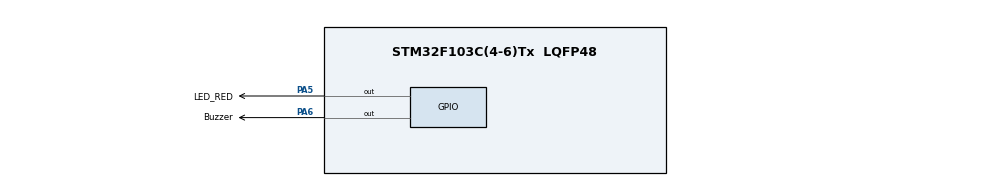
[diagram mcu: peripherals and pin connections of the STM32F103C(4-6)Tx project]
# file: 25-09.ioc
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Mcu.Family=STM32F1
Mcu.Name=STM32F103C(4-6)Tx
Mcu.Package=LQFP48
NVIC.PriorityGroup=NVIC_PRIORITYGROUP_4
NVIC.TIM2_IRQn=true\:0\:0\:false\:false\:true\:true\:true
PA5.GPIO_Label=LED_RED
PA5.Signal=GPIO_Output
PA6.GPIO_Label=Buzzer
PA6.Signal=GPIO_Output
ProjectManager.HeapSize=0x200
ProjectManager.StackSize=0x400
ProjectManager.TargetToolchain=STM32CubeIDE
RCC.APB1Freq_Value=8000000
RCC.APB2Freq_Value=8000000
TIM2.Period=9
TIM2.Prescaler=7999
VP_SYS_VS_ND.Mode=No_Debug
VP_TIM2_VS_ClockSourceINT.Mode=Internal
board=custom

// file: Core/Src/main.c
/* USER CODE BEGIN Header */
/**
  ******************************************************************************
  * @file           : main.c
  * @brief          : Main program body
  ******************************************************************************
  * @attention
  *
  * <h2><center>&copy; Copyright (c) 2022 STMicroelectronics.
  * All rights reserved.</center></h2>
  *
  * This software component is licensed by ST under BSD 3-Clause license,
  * the "License"; You may not use this file except in compliance with the
  * License. You may obtain a copy of the License at:
  *                        opensource.org/licenses/BSD-3-Clause
  *
  ******************************************************************************
  */
/* USER CODE END Header */
#include "main.h"

/* USER CODE BEGIN Includes */
#include "software_timer.h"
/* USER CODE END Includes */

TIM_HandleTypeDef htim2;

void SystemClock_Config(void);
static void MX_GPIO_Init(void);
static void MX_TIM2_Init(void);
void Turn_On_LED (void);
void Turn_Off_LED (void);
void Turn_On_Buzzer (void);
void Turn_Off_Buzzer (void);
void SystemStatusUpdate (void);
const uint8_t delayTime = 10;
static uint32_t ledOnTime, ledOffTime, u32CounterForSystemStatus, u8systemStatus;

/* USER CODE BEGIN 0 */
void Led_Setup(uint32_t onTime, uint32_t offTime){
	if(delayTime != 0){
		ledOnTime = onTime*1000/delayTime;
		ledOffTime = offTime*1000/delayTime;
	}
}
void Turn_On_LED (void)
{
	HAL_GPIO_WritePin(LED_RED_GPIO_Port, LED_RED_Pin, 1);
}
void Turn_Off_LED (void)
{
	HAL_GPIO_WritePin(LED_RED_GPIO_Port, LED_RED_Pin, 0);
}
void Turn_On_Buzzer (void)
{
	HAL_GPIO_WritePin(Buzzer_GPIO_Port, Buzzer_Pin, 1);
}
void Turn_Off_Buzzer (void)
{
	HAL_GPIO_WritePin(Buzzer_GPIO_Port, Buzzer_Pin, 0);
}
void SystemStatusUpdate (void)
{
	u32CounterForSystemStatus = (u32CounterForSystemStatus+1)%600;//600 x 10ms =6s
	if(u32CounterForSystemStatus==0)
	{
		u8systemStatus=(u8systemStatus+1)%4;
	}
}

//this function will be invoked the timer interrupt in every 10ms
//assume TI is 10ms
void Timer_Interrupt_Service_Routine(void)
{
	SystemStatusUpdate();
}

void System_Status_On_Processing(void)
{
	if(u8systemStatus==1)
	{
		Led_Setup(1,1);
	}
}
/* USER CODE END 0 */

int main(void)
{

  /* MCU Configuration--------------------------------------------------------*/

  /* Reset of all peripherals, Initializes the Flash interface and the Systick. */
  HAL_Init();

  /* Configure the system clock */
  SystemClock_Config();

  /* Initialize all configured peripherals */
  MX_GPIO_Init();
  MX_TIM2_Init();
  /* USER CODE BEGIN 2 */
  HAL_TIM_Base_Start_IT(&htim2);
  /* USER CODE END 2 */

  /* Infinite loop */
  /* USER CODE BEGIN WHILE */
  setTimer1(100);
  while (1)
  {
	  if(timer1_flag == 1){
		  setTimer1(100);
		  //TODO
		  HAL_GPIO_TogglePin(LED_RED_GPIO_Port, LED_RED_Pin);
	  }
    /* USER CODE END WHILE */

  }
}

void SystemClock_Config(void)
{
  RCC_OscInitTypeDef RCC_OscInitStruct = {0};
  RCC_ClkInitTypeDef RCC_ClkInitStruct = {0};

  /** Initializes the RCC Oscillators according to the specified parameters
  * in the RCC_OscInitTypeDef structure.
  */
  RCC_OscInitStruct.OscillatorType = RCC_OSCILLATORTYPE_HSI;
  RCC_OscInitStruct.HSIState = RCC_HSI_ON;
  RCC_OscInitStruct.HSICalibrationValue = RCC_HSICALIBRATION_DEFAULT;
  RCC_OscInitStruct.PLL.PLLState = RCC_PLL_NONE;
  if (HAL_RCC_OscConfig(&RCC_OscInitStruct) != HAL_OK)
  {
    Error_Handler();
  }
  /** Initializes the CPU, AHB and APB buses clocks
  */
  RCC_ClkInitStruct.ClockType = RCC_CLOCKTYPE_HCLK|RCC_CLOCKTYPE_SYSCLK
                              |RCC_CLOCKTYPE_PCLK1|RCC_CLOCKTYPE_PCLK2;
  RCC_ClkInitStruct.SYSCLKSource = RCC_SYSCLKSOURCE_HSI;
  RCC_ClkInitStruct.AHBCLKDivider = RCC_SYSCLK_DIV1;
  RCC_ClkInitStruct.APB1CLKDivider = RCC_HCLK_DIV1;
  RCC_ClkInitStruct.APB2CLKDivider = RCC_HCLK_DIV1;

  if (HAL_RCC_ClockConfig(&RCC_ClkInitStruct, FLASH_LATENCY_0) != HAL_OK)
  {
    Error_Handler();
  }
}

static void MX_TIM2_Init(void)
{

  TIM_ClockConfigTypeDef sClockSourceConfig = {0};
  TIM_MasterConfigTypeDef sMasterConfig = {0};

  htim2.Instance = TIM2;
  htim2.Init.Prescaler = 7999;
  htim2.Init.CounterMode = TIM_COUNTERMODE_UP;
  htim2.Init.Period = 9;
  htim2.Init.ClockDivision = TIM_CLOCKDIVISION_DIV1;
  htim2.Init.AutoReloadPreload = TIM_AUTORELOAD_PRELOAD_DISABLE;
  if (HAL_TIM_Base_Init(&htim2) != HAL_OK)
  {
    Error_Handler();
  }
  sClockSourceConfig.ClockSource = TIM_CLOCKSOURCE_INTERNAL;
  if (HAL_TIM_ConfigClockSource(&htim2, &sClockSourceConfig) != HAL_OK)
  {
    Error_Handler();
  }
  sMasterConfig.MasterOutputTrigger = TIM_TRGO_RESET;
  sMasterConfig.MasterSlaveMode = TIM_MASTERSLAVEMODE_DISABLE;
  if (HAL_TIMEx_MasterConfigSynchronization(&htim2, &sMasterConfig) != HAL_OK)
  {
    Error_Handler();
  }

}

static void MX_GPIO_Init(void)
{
  GPIO_InitTypeDef GPIO_InitStruct = {0};

  /* GPIO Ports Clock Enable */
  __HAL_RCC_GPIOA_CLK_ENABLE();

  /*Configure GPIO pin Output Level */
  HAL_GPIO_WritePin(GPIOA, LED_RED_Pin|Buzzer_Pin, GPIO_PIN_RESET);

  /*Configure GPIO pins : LED_RED_Pin Buzzer_Pin */
  GPIO_InitStruct.Pin = LED_RED_Pin|Buzzer_Pin;
  GPIO_InitStruct.Mode = GPIO_MODE_OUTPUT_PP;
  GPIO_InitStruct.Pull = GPIO_NOPULL;
  GPIO_InitStruct.Speed = GPIO_SPEED_FREQ_LOW;
  HAL_GPIO_Init(GPIOA, &GPIO_InitStruct);

}

/* USER CODE BEGIN 4 */
void HAL_TIM_PeriodElapsedCallback(TIM_HandleTypeDef *htim){
	timerRun();
}
/* USER CODE END 4 */

void Error_Handler(void)
{
  __disable_irq();
  while (1)
  {
  }
}

/************************ (C) COPYRIGHT STMicroelectronics *****END OF FILE****/
